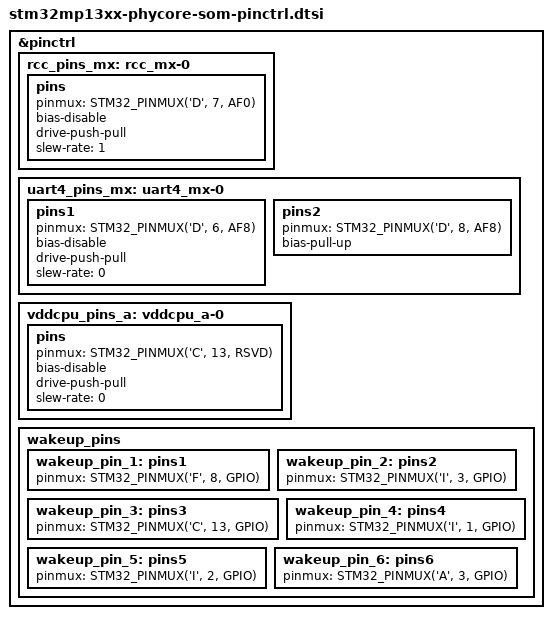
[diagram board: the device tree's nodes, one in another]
// SPDX-License-Identifier: (GPL-2.0+ OR BSD-3-Clause)
/*
 * Copyright (C) 2023 PHYTEC Messtechnik GmbH
 * Author: Christophe Parant <c.parant@phytec.fr>
 */

#include <dt-bindings/pinctrl/stm32-pinfunc.h>

&pinctrl {
	rcc_pins_mx: rcc_mx-0 {
		pins {
			pinmux = <STM32_PINMUX('D', 7, AF0)>; /* RCC_MCO_1 */
			bias-disable;
			drive-push-pull;
			slew-rate = <1>;
		};
	};

	uart4_pins_mx: uart4_mx-0 {
		pins1 {
			pinmux = <STM32_PINMUX('D', 6, AF8)>; /* UART4_TX */
			bias-disable;
			drive-push-pull;
			slew-rate = <0>;
		};
		pins2 {
			pinmux = <STM32_PINMUX('D', 8, AF8)>; /* UART4_RX */
			bias-pull-up;
		};
	};

	vddcpu_pins_a: vddcpu_a-0 {
		pins {
			pinmux = <STM32_PINMUX('C', 13, RSVD)>; /* X_OD_OPP */
			bias-disable;
			drive-push-pull;
			slew-rate = <0>;
		};
	};

	wakeup_pins: wakeup_pins {
		wakeup_pin_1: pins1 {
			pinmux = <STM32_PINMUX('F', 8, GPIO)>;
		};
		wakeup_pin_2: pins2 {
			pinmux = <STM32_PINMUX('I', 3, GPIO)>;
		};
		wakeup_pin_3: pins3 {
			pinmux = <STM32_PINMUX('C', 13, GPIO)>;
		};
		wakeup_pin_4: pins4 {
			pinmux = <STM32_PINMUX('I', 1, GPIO)>;
		};
		wakeup_pin_5: pins5 {
			pinmux = <STM32_PINMUX('I', 2, GPIO)>;
		};
		wakeup_pin_6: pins6 {
			pinmux = <STM32_PINMUX('A', 3, GPIO)>;
		};
	};
};
